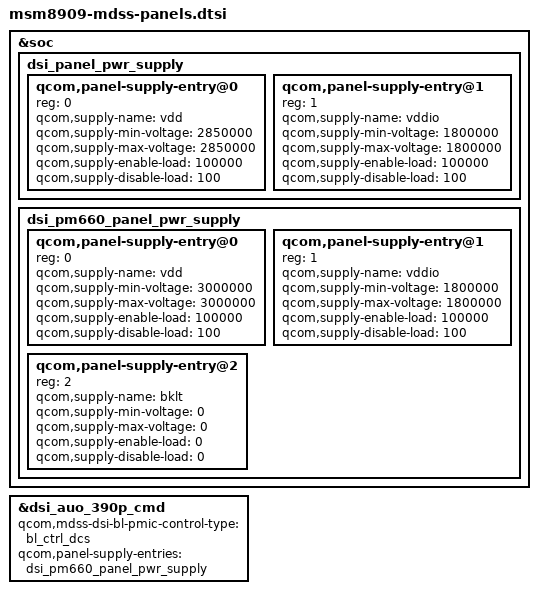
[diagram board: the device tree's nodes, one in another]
/* Copyright (c) 2014-2018, The Linux Foundation. All rights reserved.
 *
 * This program is free software; you can redistribute it and/or modify
 * it under the terms of the GNU General Public License version 2 and
 * only version 2 as published by the Free Software Foundation.
 *
 * This program is distributed in the hope that it will be useful,
 * but WITHOUT ANY WARRANTY; without even the implied warranty of
 * MERCHANTABILITY or FITNESS FOR A PARTICULAR PURPOSE.  See the
 * GNU General Public License for more details.
 */

#include "dsi-panel-390p-auo-cmd.dtsi"

&soc {
	dsi_panel_pwr_supply: dsi_panel_pwr_supply {
		#address-cells = <1>;
		#size-cells = <0>;

		qcom,panel-supply-entry@0 {
			reg = <0>;
			qcom,supply-name = "vdd";
			qcom,supply-min-voltage = <2850000>;
			qcom,supply-max-voltage = <2850000>;
			qcom,supply-enable-load = <100000>;
			qcom,supply-disable-load = <100>;
		};

		qcom,panel-supply-entry@1 {
			reg = <1>;
			qcom,supply-name = "vddio";
			qcom,supply-min-voltage = <1800000>;
			qcom,supply-max-voltage = <1800000>;
			qcom,supply-enable-load = <100000>;
			qcom,supply-disable-load = <100>;
		};
	};

	dsi_pm660_panel_pwr_supply: dsi_pm660_panel_pwr_supply {
		#address-cells = <1>;
		#size-cells = <0>;

		qcom,panel-supply-entry@0 {
			reg = <0>;
			qcom,supply-name = "vdd";
			qcom,supply-min-voltage = <3000000>;
			qcom,supply-max-voltage = <3000000>;
			qcom,supply-enable-load = <100000>;
			qcom,supply-disable-load = <100>;
		};

		qcom,panel-supply-entry@1 {
			reg = <1>;
			qcom,supply-name = "vddio";
			qcom,supply-min-voltage = <1800000>;
			qcom,supply-max-voltage = <1800000>;
			qcom,supply-enable-load = <100000>;
			qcom,supply-disable-load = <100>;
		};

		qcom,panel-supply-entry@2 {
			reg = <2>;
			qcom,supply-name = "bklt";
			qcom,supply-min-voltage = <0>;
			qcom,supply-max-voltage = <0>;
			qcom,supply-enable-load = <0>;
			qcom,supply-disable-load = <0>;
		};
	};
};

&dsi_auo_390p_cmd {
	qcom,mdss-dsi-bl-pmic-control-type = "bl_ctrl_dcs";
	qcom,panel-supply-entries = <&dsi_pm660_panel_pwr_supply>;
};
